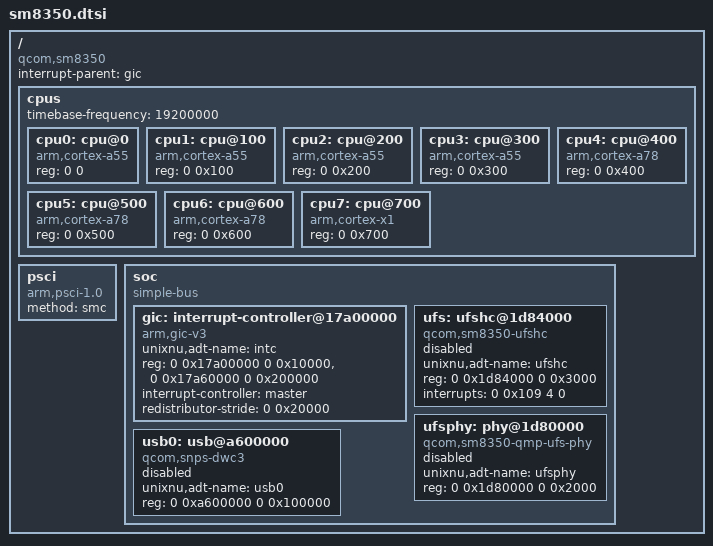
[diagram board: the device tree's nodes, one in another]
// SPDX-License-Identifier: BSD-3-Clause
// Qualcomm SM8350 (lahaina) shared hardware description.
// Values cross-checked against the live firmware FDT of a Redmi K40 Pro (haydn):
//   /sys/firmware/fdt -> decompiled, see UniXNU-haydn/docs/haydn-fdt.dts
/ {
    compatible = "qcom,sm8350";
    #address-cells = <2>;
    #size-cells = <2>;
    interrupt-parent = <&gic>;

    cpus {
        #address-cells = <2>;
        #size-cells = <0>;
        // 19.2 MHz always-on XO, /soc/timer on lahaina
        timebase-frequency = <19200000>;
        cpu0: cpu@0 { device_type = "cpu"; compatible = "arm,cortex-a55"; reg = <0 0>; };
        cpu1: cpu@100 { device_type = "cpu"; compatible = "arm,cortex-a55"; reg = <0 0x100>; };
        cpu2: cpu@200 { device_type = "cpu"; compatible = "arm,cortex-a55"; reg = <0 0x200>; };
        cpu3: cpu@300 { device_type = "cpu"; compatible = "arm,cortex-a55"; reg = <0 0x300>; };
        cpu4: cpu@400 { device_type = "cpu"; compatible = "arm,cortex-a78"; reg = <0 0x400>; };
        cpu5: cpu@500 { device_type = "cpu"; compatible = "arm,cortex-a78"; reg = <0 0x500>; };
        cpu6: cpu@600 { device_type = "cpu"; compatible = "arm,cortex-a78"; reg = <0 0x600>; };
        cpu7: cpu@700 { device_type = "cpu"; compatible = "arm,cortex-x1"; reg = <0 0x700>; };
    };

    psci { compatible = "arm,psci-1.0"; method = "smc"; };

    soc {
        compatible = "simple-bus";
        #address-cells = <2>;
        #size-cells = <2>;
        ranges;

        gic: interrupt-controller@17a00000 {
            compatible = "arm,gic-v3";
            unixnu,adt-name = "intc";
            reg = <0 0x17a00000 0 0x10000>, <0 0x17a60000 0 0x200000>;
            #interrupt-cells = <4>;
            #address-cells = <0>;
            interrupt-controller = "master";
            redistributor-stride = <0 0x20000>;
        };

        ufs: ufshc@1d84000 {
            compatible = "qcom,sm8350-ufshc";
            unixnu,adt-name = "ufshc";
            reg = <0 0x1d84000 0 0x3000>;
            interrupts = <0 0x109 4 0>;
            status = "disabled";
        };

        ufsphy: phy@1d80000 {
            compatible = "qcom,sm8350-qmp-ufs-phy";
            unixnu,adt-name = "ufsphy";
            reg = <0 0x1d80000 0 0x2000>;
            status = "disabled";
        };

        usb0: usb@a600000 {
            compatible = "qcom,snps-dwc3";
            unixnu,adt-name = "usb0";
            reg = <0 0xa600000 0 0x100000>;
            status = "disabled";
        };
    };
};
